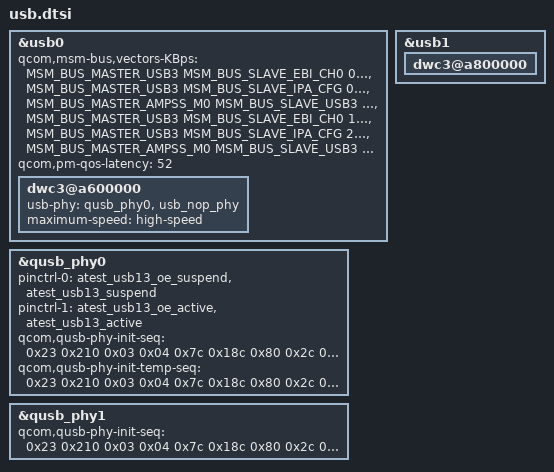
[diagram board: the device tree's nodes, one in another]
/*
 * Copyright (c) 2024, MeizuCustoms enthusiasts
 *
 * This program is free software; you can redistribute it and/or modify
 * it under the terms of the GNU General Public License version 2 and
 * only version 2 as published by the Free Software Foundation.
 *
 * This program is distributed in the hope that it will be useful,
 * but WITHOUT ANY WARRANTY; without even the implied warranty of
 * MERCHANTABILITY or FITNESS FOR A PARTICULAR PURPOSE.  See the
 * GNU General Public License for more details.
 */

&usb0 {
	qcom,msm-bus,vectors-KBps =
		<MSM_BUS_MASTER_USB3 MSM_BUS_SLAVE_EBI_CH0 0 0>,
		<MSM_BUS_MASTER_USB3 MSM_BUS_SLAVE_IPA_CFG 0 0>,
		<MSM_BUS_MASTER_AMPSS_M0 MSM_BUS_SLAVE_USB3 0 0>,
		<MSM_BUS_MASTER_USB3
			MSM_BUS_SLAVE_EBI_CH0 1000000 1400000>,
		<MSM_BUS_MASTER_USB3
			MSM_BUS_SLAVE_IPA_CFG 2400 4800>,
		<MSM_BUS_MASTER_AMPSS_M0 MSM_BUS_SLAVE_USB3 0 40000>;
	qcom,pm-qos-latency = <52>;

	dwc3@a600000 {
		usb-phy = <&qusb_phy0>, <&usb_nop_phy>;
		maximum-speed = "high-speed";
	};
};

&usb1 {
	status = "ok";

	dwc3@a800000 {
		/delete-property/ dr_mode;
	};
};

&qusb_phy0 {
	pinctrl-names = "atest_usb13_suspend", "atest_usb13_active";
	pinctrl-0 = <&atest_usb13_oe_suspend &atest_usb13_suspend>;
	pinctrl-1 = <&atest_usb13_oe_active &atest_usb13_active>;

	qcom,qusb-phy-init-seq =
	/* <value reg_offset> */
		<0x23 0x210 /* PWR_CTRL1 */
		 0x03 0x04  /* PLL_ANALOG_CONTROLS_TWO */
		 0x7c 0x18c /* PLL_CLOCK_INVERTERS */
		 0x80 0x2c  /* PLL_CMODE */
		 0x0a 0x184 /* PLL_LOCK_DELAY */
		 0x19 0xb4  /* PLL_DIGITAL_TIMERS_TWO */
		 0x40 0x194 /* PLL_BIAS_CONTROL_1 */
		 0x17 0x198 /* PLL_BIAS_CONTROL_2 */
		 0x21 0x214 /* PWR_CTRL2 */
		 0x08 0x220 /* IMP_CTRL1 */
		 0x58 0x224 /* IMP_CTRL2 */
		 0x45 0x240 /* TUNE1 */
		 0x29 0x244 /* TUNE2 */
		 0xca 0x248 /* TUNE3 */
		 0x04 0x24c /* TUNE4 */
		 0x03 0x250 /* TUNE5 */
		 0x00 0x23c /* CHG_CTRL2 */
		 0x22 0x210>; /* PWR_CTRL1 */

	qcom,qusb-phy-init-temp-seq =
	/* <value reg_offset> */
		<0x23 0x210 /* PWR_CTRL1 */
		 0x03 0x04  /* PLL_ANALOG_CONTROLS_TWO */
		 0x7c 0x18c /* PLL_CLOCK_INVERTERS */
		 0x80 0x2c  /* PLL_CMODE */
		 0x0a 0x184 /* PLL_LOCK_DELAY */
		 0x19 0xb4  /* PLL_DIGITAL_TIMERS_TWO */
		 0x40 0x194 /* PLL_BIAS_CONTROL_1 */
		 0x20 0x198 /* PLL_BIAS_CONTROL_2 */
		 0x21 0x214 /* PWR_CTRL2 */
		 0x00 0x220 /* IMP_CTRL1 */
		 0x58 0x224 /* IMP_CTRL2 */
		 0x30 0x240 /* TUNE1 */
		 0x29 0x244 /* TUNE2 */
		 0xca 0x248 /* TUNE3 */
		 0x04 0x24c /* TUNE4 */
		 0x03 0x250 /* TUNE5 */
		 0x00 0x23c /* CHG_CTRL2 */
		 0x22 0x210>; /* PWR_CTRL1 */

	/delete-property/ qcom,override-bias-ctrl2;
};

&qusb_phy1 {
	qcom,qusb-phy-init-seq =
	/* <value reg_offset> */
		<0x23 0x210 /* PWR_CTRL1 */
		 0x03 0x04  /* PLL_ANALOG_CONTROLS_TWO */
		 0x7c 0x18c /* PLL_CLOCK_INVERTERS */
		 0x80 0x2c  /* PLL_CMODE */
		 0x0a 0x184 /* PLL_LOCK_DELAY */
		 0x19 0xb4  /* PLL_DIGITAL_TIMERS_TWO */
		 0x40 0x194 /* PLL_BIAS_CONTROL_1 */
		 0x17 0x198 /* PLL_BIAS_CONTROL_2 */
		 0x21 0x214 /* PWR_CTRL2 */
		 0x00 0x220 /* IMP_CTRL1 */
		 0x58 0x224 /* IMP_CTRL2 */
		 0x20 0x240 /* TUNE1 */
		 0x29 0x244 /* TUNE2 */
		 0xca 0x248 /* TUNE3 */
		 0x04 0x24c /* TUNE4 */
		 0x03 0x250 /* TUNE5 */
		 0x00 0x23c /* CHG_CTRL2 */
		 0x22 0x210>; /* PWR_CTRL1 */

	status = "ok";
	/delete-property/ qcom,override-bias-ctrl2;
};
